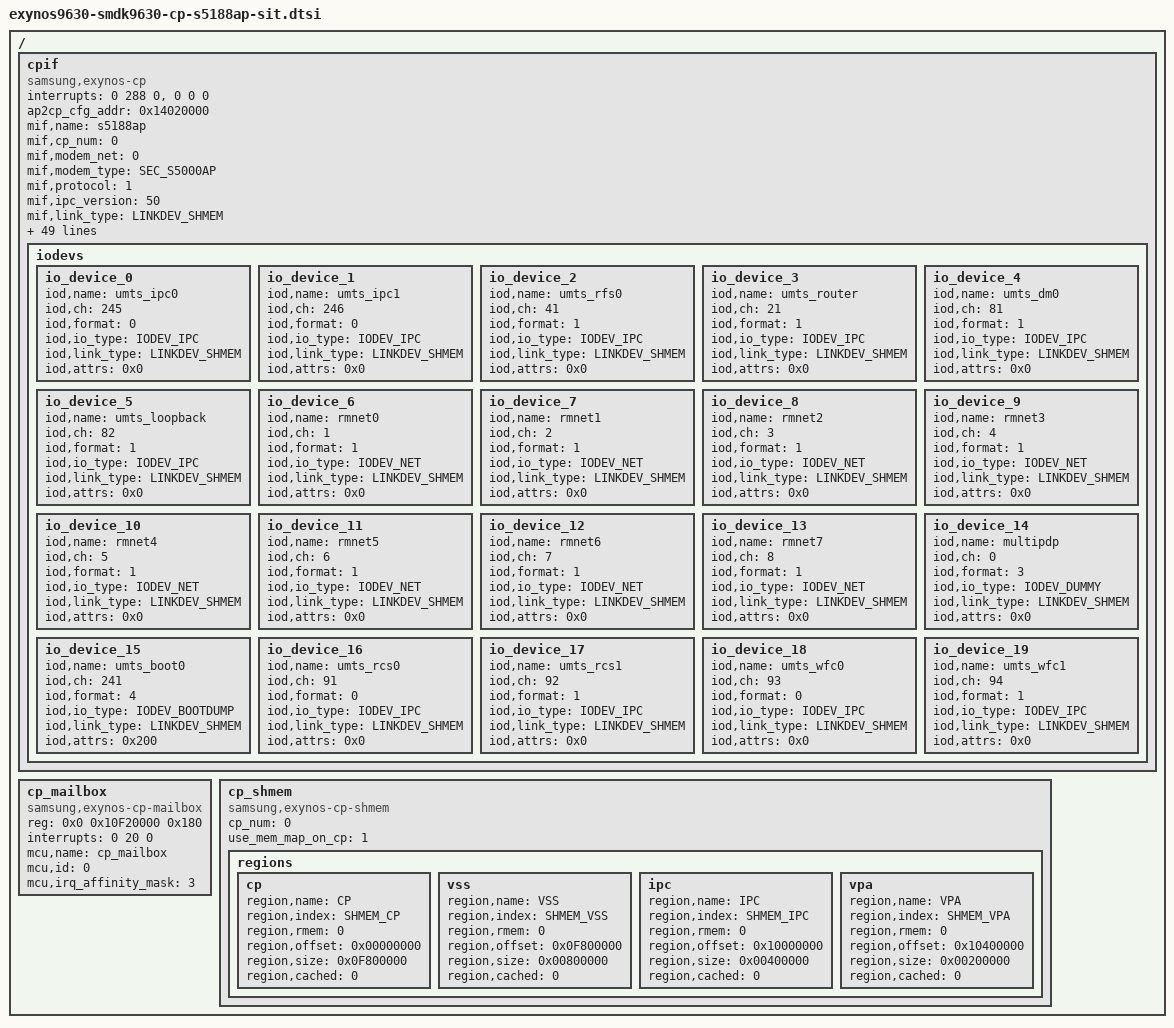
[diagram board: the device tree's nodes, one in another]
/*
 * Samsung CP interface device tree source
 *
 * Copyright (c) 2019 Samsung Electronics Co., Ltd.
 *             http://www.samsung.com
 *
 * This program is free software; you can redistribute it and/or modify
 * it under the terms of the GNU General Public License version 2 as
 * published by the Free Software Foundation.
 */

#include <dt-bindings/soc/samsung/exynos-cpif.h>

/ {
	fragment@modemif {
		target-path = "/";
		__overlay__ {
			#address-cells = <2>;
			#size-cells = <1>;

			/* Modem interface information */
			cpif {
				compatible = "samsung,exynos-cp";
				status = "okay";

				interrupts = <0 288 0>, <0 0 0>;
				interrupt-names = "RESET_REQ", "CP_ACTIVE";

				ap2cp_cfg_addr = <0x14020000>;

				/* */
				mif,name = "s5188ap";
				mif,cp_num = <0>;
				mif,modem_net = <0>;		/* UMTS_NETWORK */
				mif,modem_type = <SEC_S5000AP>;
				mif,protocol = <1>;
				mif,ipc_version = <50>;
				mif,link_type = <LINKDEV_SHMEM>;
				mif,link_name = "shmem";
				mif,link_attrs = <(LINK_ATTR_MASK_XMIT_BTDLR | LINK_ATTR_MASK_DUMP_ALIGNED | LINK_ATTR_MASK_BOOT_ALIGNED | LINK_ATTR_MASK_MEM_DUMP | LINK_ATTR_MASK_MEM_BOOT | LINK_ATTR_MASK_DPRAM_MAGIC)>;
				mif,interrupt_types = <INTERRUPT_MAILBOX>;
				mif,sim_socket_num = <2>;		/* sim socket num */
				shmem,dump_offset = <0x1000>;

				/* Mailbox interrupt number from AP to CP */
				mif,int_ap2cp_msg = <0>;
				mif,int_ap2cp_wakeup = <1>;
				mif,int_ap2cp_status = <2>;
				mif,int_ap2cp_active = <3>;

				/* Mailbox interrupt number from CP to AP */
				mif,irq_cp2ap_msg = <0>;
				mif,irq_cp2ap_status = <2>;
				mif,irq_cp2ap_active = <3>;
				mif,irq_cp2ap_perf_req_cpu = <5>;
				mif,irq_cp2ap_perf_req_mif = <6>;
				mif,irq_cp2ap_perf_req_int = <7>;
				mif,irq_cp2ap_wakelock = <8>;
				mif,irq_cp2ap_ratmode = <9>;

				mif,control_msg_type = <DRAM>;
				/* DRAM offsets */
				offset_ap_version = <0x28>;
				offset_cp_version = <0x2C>;
				offset_cmsg_offset = <0x30>;
				offset_srinfo_offset = <0x34>;
				offset_clk_table_offset = <0x38>;
				offset_buff_desc_offset = <0x3C>;

				/* Status bit info for mbx_ap2cp_united_status */
				sbi_crash_type_mask = <0xf>;
				sbi_crash_type_pos = <23>;
				sbi_ext_backtrace_mask = <0x1>;
				sbi_ext_backtrace_pos = <17>;
				sbi_ds_det_mask = <0x3>;
				sbi_ds_det_pos = <14>;
				sbi_sys_rev_mask = <0xff>;
				sbi_sys_rev_pos = <6>;
				sbi_pda_active_mask = <0x1>;
				sbi_pda_active_pos = <5>;
				sbi_ap_status_mask = <0xf>;
				sbi_ap_status_pos = <1>;

				/* Status bit info for mbx_cp2ap_united_status */
				sbi_cp_rat_mode_mask = <0x3f>;
				sbi_cp_rat_mode_pos = <26>;
				sbi_cp_evs_mode_mask = <0x1>;
				sbi_cp_evs_mode_pos = <7>;
				sbi_cp2ap_wakelock_mask = <0x1>;
				sbi_cp2ap_wakelock_pos = <6>;
				sbi_lte_active_mask = <0x1>;
				sbi_lte_active_pos = <5>;
				sbi_cp_status_mask = <0xf>;
				sbi_cp_status_pos = <1>;

				/* CP BTL (Back Trace Log) */
				cp_btl_node_name = "ramdump_memshare";

				/* IO devices */
				mif,num_iodevs = <20>;
				iodevs {
					io_device_0 {
						iod,name = "umts_ipc0";
						iod,ch = <245>;
						iod,format = <0>;		/* IPC_FMT */
						iod,io_type = <IODEV_IPC>;
						iod,link_type = <LINKDEV_SHMEM>;
						iod,attrs = <0x0>;
					};
					io_device_1 {
						iod,name = "umts_ipc1";
						iod,ch = <246>;
						iod,format = <0>;		/* IPC_FMT */
						iod,io_type = <IODEV_IPC>;
						iod,link_type = <LINKDEV_SHMEM>;
						iod,attrs = <0x0>;
					};
					io_device_2 {
						iod,name = "umts_rfs0";
						iod,ch = <41>;
						iod,format = <1>;		/* IPC_RAW?? */
						iod,io_type = <IODEV_IPC>;
						iod,link_type = <LINKDEV_SHMEM>;
						iod,attrs = <0x0>;
					};
					io_device_3 {
						iod,name = "umts_router";
						iod,ch = <21>;
						iod,format = <1>;		/* IPC_RAW */
						iod,io_type = <IODEV_IPC>;
						iod,link_type = <LINKDEV_SHMEM>;
						iod,attrs = <0x0>;
					};
					io_device_4 {
						iod,name = "umts_dm0";
						iod,ch = <81>;
						iod,format = <1>;		/* IPC_RAW */
						iod,io_type = <IODEV_IPC>;
						iod,link_type = <LINKDEV_SHMEM>;
						iod,attrs = <0x0>;
					};
					io_device_5 {
						iod,name = "umts_loopback";
						iod,ch = <82>;
						iod,format = <1>;		/* IPC_FMT */
						iod,io_type = <IODEV_IPC>;
						iod,link_type = <LINKDEV_SHMEM>;
						iod,attrs = <0x0>;
					};
					io_device_6 {
						iod,name = "rmnet0";
						iod,ch = <1>;
						iod,format = <1>;		/* IPC_RAW */
						iod,io_type = <IODEV_NET>;
						iod,link_type = <LINKDEV_SHMEM>;
						iod,attrs = <0x0>;
					};
					io_device_7 {
						iod,name = "rmnet1";
						iod,ch = <2>;
						iod,format = <1>;		/* IPC_RAW */
						iod,io_type = <IODEV_NET>;
						iod,link_type = <LINKDEV_SHMEM>;
						iod,attrs = <0x0>;
					};
					io_device_8 {
						iod,name = "rmnet2";
						iod,ch = <3>;
						iod,format = <1>;		/* IPC_RAW */
						iod,io_type = <IODEV_NET>;
						iod,link_type = <LINKDEV_SHMEM>;
						iod,attrs = <0x0>;
					};
					io_device_9 {
						iod,name = "rmnet3";
						iod,ch = <4>;
						iod,format = <1>;		/* IPC_RAW */
						iod,io_type = <IODEV_NET>;
						iod,link_type = <LINKDEV_SHMEM>;
						iod,attrs = <0x0>;
					};
					io_device_10 {
						iod,name = "rmnet4";
						iod,ch = <5>;
						iod,format = <1>;		/* IPC_RAW */
						iod,io_type = <IODEV_NET>;
						iod,link_type = <LINKDEV_SHMEM>;
						iod,attrs = <0x0>;
					};
					io_device_11 {
						iod,name = "rmnet5";
						iod,ch = <6>;
						iod,format = <1>;		/* IPC_RAW */
						iod,io_type = <IODEV_NET>;
						iod,link_type = <LINKDEV_SHMEM>;
						iod,attrs = <0x0>;
					};
					io_device_12 {
						iod,name = "rmnet6";
						iod,ch = <7>;
						iod,format = <1>;		/* IPC_RAW */
						iod,io_type = <IODEV_NET>;
						iod,link_type = <LINKDEV_SHMEM>;
						iod,attrs = <0x0>;
					};
					io_device_13 {
						iod,name = "rmnet7";
						iod,ch = <8>;
						iod,format = <1>;		/* IPC_RAW */
						iod,io_type = <IODEV_NET>;
						iod,link_type = <LINKDEV_SHMEM>;
						iod,attrs = <0x0>;
					};
					io_device_14 {
						iod,name = "multipdp";
						iod,ch = <0>;
						iod,format = <3>;		/* IPC_MULTI_RAW */
						iod,io_type = <IODEV_DUMMY>;
						iod,link_type = <LINKDEV_SHMEM>;
						iod,attrs = <0x0>;
					};
					io_device_15 {
						iod,name = "umts_boot0";
						iod,ch = <241>;
						iod,format = <4>;		/* IPC_BOOT */
						iod,io_type = <IODEV_BOOTDUMP>;
						iod,link_type = <LINKDEV_SHMEM>;
						iod,attrs = <0x200>;		/* ATTR_NO_CHECK_MAXQ*/
					};
					io_device_16 {
						iod,name = "umts_rcs0";
						iod,ch = <91>;
						iod,format = <0>;		/* IPC_FMT */
						iod,io_type = <IODEV_IPC>;
						iod,link_type = <LINKDEV_SHMEM>;
						iod,attrs = <0x0>;
					};
					io_device_17 {
						iod,name = "umts_rcs1";
						iod,ch = <92>;
						iod,format = <1>;		/* IPC_RAW */
						iod,io_type = <IODEV_IPC>;
						iod,link_type = <LINKDEV_SHMEM>;
						iod,attrs = <0x0>;
					};
					io_device_18 {
						iod,name = "umts_wfc0";
						iod,ch = <93>;
						iod,format = <0>;		/* IPC_FMT */
						iod,io_type = <IODEV_IPC>;
						iod,link_type = <LINKDEV_SHMEM>;
						iod,attrs = <0x0>;
					};
					io_device_19 {
						iod,name = "umts_wfc1";
						iod,ch = <94>;
						iod,format = <1>;		/* IPC_RAW */
						iod,io_type = <IODEV_IPC>;
						iod,link_type = <LINKDEV_SHMEM>;
						iod,attrs = <0x0>;
					};
				}; /* end of iodevs */
			}; /* end of cpif */

			/* Mailbox information */
			cp_mailbox {
				compatible = "samsung,exynos-cp-mailbox";

				reg = <0x0 0x10F20000 0x180>;
				interrupts = <0 20 0>;

				mcu,name = "cp_mailbox";
				mcu,id = <0>;
				mcu,irq_affinity_mask = <3>;
			};

			/* Shared memory information*/
			cp_shmem {
				compatible = "samsung,exynos-cp-shmem";

				cp_num = <0>;
				use_mem_map_on_cp = <1>;

				regions {
					cp {
						region,name = "CP";
						region,index = <SHMEM_CP>;
						region,rmem = <0>;
						region,offset = <0x00000000>;
						region,size = <0x0F800000>;
						region,cached = <0>;
					};
					vss {
						region,name = "VSS";
						region,index = <SHMEM_VSS>;
						region,rmem = <0>;
						region,offset = <0x0F800000>;
						region,size = <0x00800000>;
						region,cached = <0>;
					};
					ipc {
						region,name = "IPC";
						region,index = <SHMEM_IPC>;
						region,rmem = <0>;
						region,offset = <0x10000000>;
						region,size = <0x00400000>;
						region,cached = <0>;
					};
					vpa {
						region,name = "VPA";
						region,index = <SHMEM_VPA>;
						region,rmem = <0>;
						region,offset = <0x10400000>;
						region,size = <0x00200000>;
						region,cached = <0>;
					};
				};
			}; /* end of cp_shmem */
		}; /* end of __overlay__ */
	}; /* end of fragment */
}; /* end of root */
